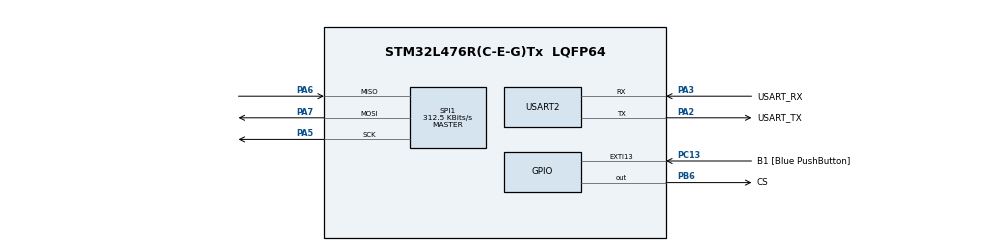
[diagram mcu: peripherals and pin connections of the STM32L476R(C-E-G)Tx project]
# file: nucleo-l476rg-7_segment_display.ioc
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Mcu.Family=STM32L4
Mcu.Name=STM32L476R(C-E-G)Tx
Mcu.Package=LQFP64
NVIC.PriorityGroup=NVIC_PRIORITYGROUP_4
PA13\ (JTMS-SWDIO).GPIO_Label=TMS
PA13\ (JTMS-SWDIO).Mode=Serial_Wire
PA13\ (JTMS-SWDIO).Signal=SYS_JTMS-SWDIO
PA14\ (JTCK-SWCLK).GPIO_Label=TCK
PA14\ (JTCK-SWCLK).Mode=Serial_Wire
PA14\ (JTCK-SWCLK).Signal=SYS_JTCK-SWCLK
PA2.GPIO_Label=USART_TX
PA2.GPIO_Mode=GPIO_MODE_AF_PP
PA2.GPIO_PuPd=GPIO_NOPULL
PA2.GPIO_Speed=GPIO_SPEED_FREQ_VERY_HIGH
PA2.Mode=Asynchronous
PA2.Signal=USART2_TX
PA3.GPIO_Label=USART_RX
PA3.GPIO_Mode=GPIO_MODE_AF_PP
PA3.GPIO_PuPd=GPIO_NOPULL
PA3.GPIO_Speed=GPIO_SPEED_FREQ_VERY_HIGH
PA3.Mode=Asynchronous
PA3.Signal=USART2_RX
PA5.Mode=Full_Duplex_Master
PA5.Signal=SPI1_SCK
PA6.Mode=Full_Duplex_Master
PA6.Signal=SPI1_MISO
PA7.Mode=Full_Duplex_Master
PA7.Signal=SPI1_MOSI
PB3\ (JTDO-TRACESWO).GPIO_Label=SWO
PB3\ (JTDO-TRACESWO).Signal=SYS_JTDO-SWO
PB6.GPIO_Label=CS
PB6.Signal=GPIO_Output
PC13.GPIO_Label=B1 [Blue PushButton]
PC13.GPIO_ModeDefaultEXTI=GPIO_MODE_IT_FALLING
PC13.GPIO_PuPd=GPIO_NOPULL
PC13.Signal=GPXTI13
PC14-OSC32_IN\ (PC14).Mode=LSE-External-Oscillator
PC14-OSC32_IN\ (PC14).Signal=RCC_OSC32_IN
PC15-OSC32_OUT\ (PC15).Mode=LSE-External-Oscillator
PC15-OSC32_OUT\ (PC15).Signal=RCC_OSC32_OUT
PH0-OSC_IN\ (PH0).Signal=RCC_OSC_IN
PH1-OSC_OUT\ (PH1).Signal=RCC_OSC_OUT
ProjectManager.HeapSize=0x200
ProjectManager.StackSize=0x400
ProjectManager.TargetToolchain=STM32CubeIDE
RCC.ADCFreq_Value=64000000
RCC.AHBFreq_Value=80000000
RCC.APB1Freq_Value=80000000
RCC.APB1TimFreq_Value=80000000
RCC.APB2Freq_Value=80000000
RCC.APB2TimFreq_Value=80000000
RCC.CortexFreq_Value=80000000
RCC.HCLKFreq_Value=80000000
RCC.HSE_VALUE=8000000
RCC.HSI_VALUE=16000000
RCC.MSI_VALUE=4000000
RCC.PLLN=10
RCC.PLLSourceVirtual=RCC_PLLSOURCE_HSI
RCC.PREFETCH_ENABLE=1
RCC.SYSCLKFreq_VALUE=80000000
RCC.SYSCLKSource=RCC_SYSCLKSOURCE_PLLCLK
RCC.USBFreq_Value=64000000
RCC.VCOOutputFreq_Value=160000000
SPI1.BaudRatePrescaler=SPI_BAUDRATEPRESCALER_256
SPI1.CalculateBaudRate=312.5 KBits/s
SPI1.DataSize=SPI_DATASIZE_8BIT
SPI1.Direction=SPI_DIRECTION_2LINES
SPI1.Mode=SPI_MODE_MASTER
SPI1.VirtualType=VM_MASTER
USART2.VirtualMode-Asynchronous=VM_ASYNC
board=NUCLEO-L476RG

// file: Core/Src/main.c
/* USER CODE BEGIN Header */

/* USER CODE END Header */
#include "main.h"

/* USER CODE BEGIN Includes */
#include "peripherals/peripherals.h"
#include <stdio.h>
#include "7seg-functions/7seg-functions.h"
/* USER CODE END Includes */

int main(void)
{

  /* MCU Configuration--------------------------------------------------------*/

  /* Reset of all peripherals, Initializes the Flash interface and the Systick. */
  HAL_Init();

  /* Configure the system clock */
  SystemClock_Config();

  /* Initialize all configured peripherals */
  MX_GPIO_Init();
  MX_USART2_UART_Init();
  MX_SPI1_Init();
  /* USER CODE BEGIN 2 */

  initializeDisplay();
  clearDisplay();
  setBrightness(254);
  HAL_Delay(2000);
  //writeTest();
  //HAL_Delay(2000);
  //startCounter();
  writeToDisplay("HELL");

  /* USER CODE END 2 */

  /* Infinite loop */
  while (1)
  {

  }
}

// /* USER CODE BEGIN 4 */

// /* USER CODE END 4 */
